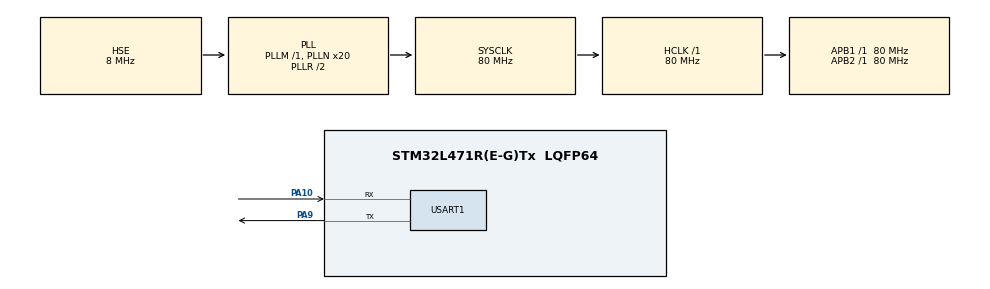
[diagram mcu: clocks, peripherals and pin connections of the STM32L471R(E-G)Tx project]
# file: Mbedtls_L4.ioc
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Dma.Request0=USART1_RX
Dma.Request1=USART1_TX
Dma.USART1_RX.0.Direction=DMA_PERIPH_TO_MEMORY
Dma.USART1_RX.0.Instance=DMA1_Channel5
Dma.USART1_RX.0.MemDataAlignment=DMA_MDATAALIGN_BYTE
Dma.USART1_RX.0.MemInc=DMA_MINC_ENABLE
Dma.USART1_RX.0.Mode=DMA_NORMAL
Dma.USART1_RX.0.PeriphDataAlignment=DMA_PDATAALIGN_BYTE
Dma.USART1_RX.0.PeriphInc=DMA_PINC_DISABLE
Dma.USART1_RX.0.Priority=DMA_PRIORITY_LOW
Dma.USART1_TX.1.Direction=DMA_MEMORY_TO_PERIPH
Dma.USART1_TX.1.Instance=DMA1_Channel4
Dma.USART1_TX.1.MemDataAlignment=DMA_MDATAALIGN_BYTE
Dma.USART1_TX.1.MemInc=DMA_MINC_ENABLE
Dma.USART1_TX.1.Mode=DMA_NORMAL
Dma.USART1_TX.1.PeriphDataAlignment=DMA_PDATAALIGN_BYTE
Dma.USART1_TX.1.PeriphInc=DMA_PINC_DISABLE
Dma.USART1_TX.1.Priority=DMA_PRIORITY_LOW
Mcu.Family=STM32L4
Mcu.Name=STM32L471R(E-G)Tx
Mcu.Package=LQFP64
NVIC.DMA1_Channel4_IRQn=true\:0\:0\:false\:false\:true\:false\:true
NVIC.DMA1_Channel5_IRQn=true\:0\:0\:false\:false\:true\:false\:true
NVIC.PriorityGroup=NVIC_PRIORITYGROUP_4
NVIC.USART1_IRQn=true\:0\:0\:false\:false\:true\:true\:true
PA10.Mode=Asynchronous
PA10.Signal=USART1_RX
PA9.Mode=Asynchronous
PA9.Signal=USART1_TX
PC14-OSC32_IN\ (PC14).Mode=LSE-External-Oscillator
PC14-OSC32_IN\ (PC14).Signal=RCC_OSC32_IN
PC15-OSC32_OUT\ (PC15).Mode=LSE-External-Oscillator
PC15-OSC32_OUT\ (PC15).Signal=RCC_OSC32_OUT
PH0-OSC_IN\ (PH0).Mode=HSE-External-Oscillator
PH0-OSC_IN\ (PH0).Signal=RCC_OSC_IN
PH1-OSC_OUT\ (PH1).Mode=HSE-External-Oscillator
PH1-OSC_OUT\ (PH1).Signal=RCC_OSC_OUT
ProjectManager.HeapSize=0x200
ProjectManager.StackSize=0x1000
ProjectManager.TargetToolchain=MDK-ARM V5.32
RCC.ADCFreq_Value=32000000
RCC.AHBFreq_Value=80000000
RCC.APB1Freq_Value=80000000
RCC.APB1TimFreq_Value=80000000
RCC.APB2Freq_Value=80000000
RCC.APB2TimFreq_Value=80000000
RCC.CortexFreq_Value=80000000
RCC.HCLKFreq_Value=80000000
RCC.HSE_VALUE=8000000
RCC.HSI_VALUE=16000000
RCC.MSI_VALUE=4000000
RCC.PLLN=20
RCC.PLLSourceVirtual=RCC_PLLSOURCE_HSE
RCC.SYSCLKFreq_VALUE=80000000
RCC.SYSCLKSource=RCC_SYSCLKSOURCE_PLLCLK
RCC.VCOOutputFreq_Value=160000000
TIM17.Prescaler=79
USART1.VirtualMode-Asynchronous=VM_ASYNC
VP_TIM17_VS_ClockSourceINT.Mode=Enable_Timer
board=custom

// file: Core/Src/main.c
/* USER CODE BEGIN Header */
/**
  ******************************************************************************
  * @file           : main.c
  * @brief          : Main program body
  ******************************************************************************
  * @attention
  *
  * Copyright (c) 2022 STMicroelectronics.
  * All rights reserved.
  *
  * This software is licensed under terms that can be found in the LICENSE file
  * in the root directory of this software component.
  * If no LICENSE file comes with this software, it is provided AS-IS.
  *
  ******************************************************************************
  */
/* USER CODE END Header */
#include "main.h"

/* USER CODE BEGIN Includes */
#include "ram_mgmt.h"
#include "delay.h"
#include "uart.h"

#include "mbedtls/md.h"

#include <string.h>
#include <stdio.h>

/* USER CODE END Includes */

/* USER CODE BEGIN PM */
#define RCV_LEN		0
#define RCV_DATA	1

/* USER CODE END PM */

TIM_HandleTypeDef htim17;

UART_HandleTypeDef huart1;
DMA_HandleTypeDef hdma_usart1_rx;
DMA_HandleTypeDef hdma_usart1_tx;

/* USER CODE BEGIN PV */
UART_Sta uart1_sta;

unsigned char rcv_flag = RCV_LEN;
unsigned char* rcv_data = NULL;
unsigned char* key = NULL;
unsigned char* msg = NULL;
int key_len = 0;
int msg_len = 0;
int data_pkg_len = 0;
unsigned char mac[64];

/* USER CODE END PV */

void SystemClock_Config(void);
static void MX_GPIO_Init(void);
static void MX_TIM17_Init(void);
static void MX_DMA_Init(void);
static void MX_USART1_UART_Init(void);

/* USER CODE BEGIN 0 */
int Parse_DataLen(unsigned char *data) {

	key_len = data[1] << 24 | data[2] << 16 | data[3] << 8 | data[4];
	msg_len = data[5] << 24 | data[6] << 16 | data[7] << 8 | data[8];

	if (key_len >= 0 && msg_len >= 0) {
		return (key_len + msg_len + 1);
	} else {
		return -1;
	}
}

void Parse_Key_Msg(unsigned char *data) {
	unsigned char *p = data;
	p++;
	key = p;
	msg = p + key_len;
}

/* USER CODE END 0 */

int main(void)
{

  /* MCU Configuration--------------------------------------------------------*/

  /* Reset of all peripherals, Initializes the Flash interface and the Systick. */
  HAL_Init();

  /* Configure the system clock */
  SystemClock_Config();

  /* Initialize all configured peripherals */
  MX_GPIO_Init();
  MX_TIM17_Init();
  MX_DMA_Init();
  MX_USART1_UART_Init();
  /* USER CODE BEGIN 2 */
  my_mem_init(SRAM1);

  UART_StaInit(&uart1_sta, &huart1, &hdma_usart1_rx);
  /* USER CODE END 2 */

  /* Infinite loop */
  while (1)
  {

    /* USER CODE BEGIN 3 */
	if (rcv_flag == RCV_LEN) {
		rcv_data = (unsigned char*)UART_WaitOnRevNumData(&uart1_sta, 9, 20);

		if (rcv_data != NULL && rcv_data[0] == 'L') {

			data_pkg_len = Parse_DataLen(rcv_data);
			my_free(SRAM1, rcv_data);
			rcv_data = NULL;

			if (data_pkg_len > 0) {
				rcv_flag = RCV_DATA;
				UART_SendNumData(&uart1_sta, "L", 1, 0);
			} else {
				// illegal data package length
			}
		} else {
			// no package received or wrong package
		}

	} else {
		rcv_data = (unsigned char*)UART_WaitOnRevNumData(&uart1_sta, data_pkg_len, 20);

		if (rcv_data != NULL && rcv_data[0] == 'D') {

			Parse_Key_Msg(rcv_data);
			my_free(SRAM1, rcv_data);
			rcv_data = NULL;

			mbedtls_md_context_t ctx;
			const mbedtls_md_info_t *info;

			mbedtls_md_init(&ctx);
			info = mbedtls_md_info_from_type(MBEDTLS_MD_SHA512);
			mbedtls_md_setup(&ctx, info, 1);

			mbedtls_md_hmac_starts(&ctx, key, key_len);
			mbedtls_md_hmac_update(&ctx, msg, msg_len);
			mbedtls_md_hmac_finish(&ctx, mac);

			mbedtls_md_free(&ctx);
			rcv_flag = RCV_LEN;

			UART_SendNumData(&uart1_sta, (char*)mac, 64, 0);
		} else {
			// no package received or wrong package
		}
	}
  }
  /* USER CODE END 3 */
}

void SystemClock_Config(void)
{
  RCC_OscInitTypeDef RCC_OscInitStruct = {0};
  RCC_ClkInitTypeDef RCC_ClkInitStruct = {0};

  /** Configure the main internal regulator output voltage
  */
  if (HAL_PWREx_ControlVoltageScaling(PWR_REGULATOR_VOLTAGE_SCALE1) != HAL_OK)
  {
    Error_Handler();
  }
  /** Initializes the RCC Oscillators according to the specified parameters
  * in the RCC_OscInitTypeDef structure.
  */
  RCC_OscInitStruct.OscillatorType = RCC_OSCILLATORTYPE_HSE;
  RCC_OscInitStruct.HSEState = RCC_HSE_ON;
  RCC_OscInitStruct.PLL.PLLState = RCC_PLL_ON;
  RCC_OscInitStruct.PLL.PLLSource = RCC_PLLSOURCE_HSE;
  RCC_OscInitStruct.PLL.PLLM = 1;
  RCC_OscInitStruct.PLL.PLLN = 20;
  RCC_OscInitStruct.PLL.PLLP = RCC_PLLP_DIV7;
  RCC_OscInitStruct.PLL.PLLQ = RCC_PLLQ_DIV2;
  RCC_OscInitStruct.PLL.PLLR = RCC_PLLR_DIV2;
  if (HAL_RCC_OscConfig(&RCC_OscInitStruct) != HAL_OK)
  {
    Error_Handler();
  }
  /** Initializes the CPU, AHB and APB buses clocks
  */
  RCC_ClkInitStruct.ClockType = RCC_CLOCKTYPE_HCLK|RCC_CLOCKTYPE_SYSCLK
                              |RCC_CLOCKTYPE_PCLK1|RCC_CLOCKTYPE_PCLK2;
  RCC_ClkInitStruct.SYSCLKSource = RCC_SYSCLKSOURCE_PLLCLK;
  RCC_ClkInitStruct.AHBCLKDivider = RCC_SYSCLK_DIV1;
  RCC_ClkInitStruct.APB1CLKDivider = RCC_HCLK_DIV1;
  RCC_ClkInitStruct.APB2CLKDivider = RCC_HCLK_DIV1;

  if (HAL_RCC_ClockConfig(&RCC_ClkInitStruct, FLASH_LATENCY_4) != HAL_OK)
  {
    Error_Handler();
  }
}

static void MX_TIM17_Init(void)
{

  htim17.Instance = TIM17;
  htim17.Init.Prescaler = 79;
  htim17.Init.CounterMode = TIM_COUNTERMODE_UP;
  htim17.Init.Period = 65535;
  htim17.Init.ClockDivision = TIM_CLOCKDIVISION_DIV1;
  htim17.Init.RepetitionCounter = 0;
  htim17.Init.AutoReloadPreload = TIM_AUTORELOAD_PRELOAD_DISABLE;
  if (HAL_TIM_Base_Init(&htim17) != HAL_OK)
  {
    Error_Handler();
  }

}

static void MX_USART1_UART_Init(void)
{

  huart1.Instance = USART1;
  huart1.Init.BaudRate = 115200;
  huart1.Init.WordLength = UART_WORDLENGTH_8B;
  huart1.Init.StopBits = UART_STOPBITS_1;
  huart1.Init.Parity = UART_PARITY_NONE;
  huart1.Init.Mode = UART_MODE_TX_RX;
  huart1.Init.HwFlowCtl = UART_HWCONTROL_NONE;
  huart1.Init.OverSampling = UART_OVERSAMPLING_16;
  huart1.Init.OneBitSampling = UART_ONE_BIT_SAMPLE_DISABLE;
  huart1.AdvancedInit.AdvFeatureInit = UART_ADVFEATURE_NO_INIT;
  if (HAL_UART_Init(&huart1) != HAL_OK)
  {
    Error_Handler();
  }

}

static void MX_DMA_Init(void)
{

  /* DMA controller clock enable */
  __HAL_RCC_DMA1_CLK_ENABLE();

  /* DMA interrupt init */
  /* DMA1_Channel4_IRQn interrupt configuration */
  HAL_NVIC_SetPriority(DMA1_Channel4_IRQn, 0, 0);
  HAL_NVIC_EnableIRQ(DMA1_Channel4_IRQn);
  /* DMA1_Channel5_IRQn interrupt configuration */
  HAL_NVIC_SetPriority(DMA1_Channel5_IRQn, 0, 0);
  HAL_NVIC_EnableIRQ(DMA1_Channel5_IRQn);

}

static void MX_GPIO_Init(void)
{

  /* GPIO Ports Clock Enable */
  __HAL_RCC_GPIOC_CLK_ENABLE();
  __HAL_RCC_GPIOH_CLK_ENABLE();
  __HAL_RCC_GPIOA_CLK_ENABLE();

}

void Error_Handler(void)
{
  __disable_irq();
  while (1)
  {
  }
}
